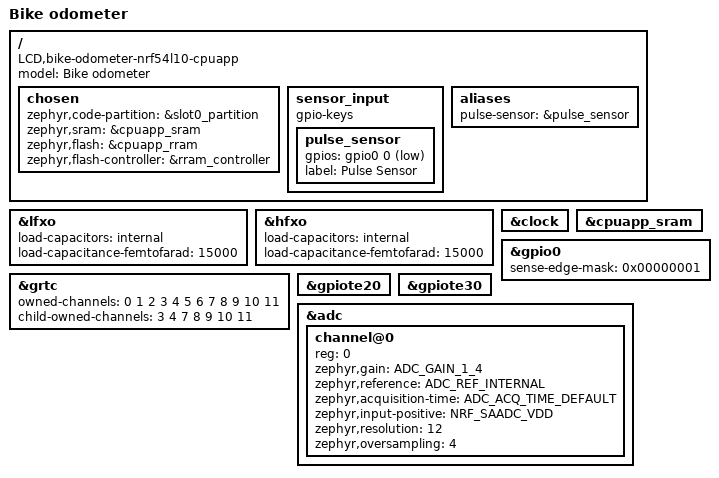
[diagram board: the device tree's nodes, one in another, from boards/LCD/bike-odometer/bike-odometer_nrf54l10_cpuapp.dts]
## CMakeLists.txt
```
#
# Copyright (c) 2018 Nordic Semiconductor
#
# SPDX-License-Identifier: LicenseRef-Nordic-5-Clause
#
cmake_minimum_required(VERSION 3.20.0)

find_package(Zephyr REQUIRED HINTS $ENV{ZEPHYR_BASE})
project(bike-odometer)

# NORDIC SDK APP START
target_sources(app PRIVATE
  src/main.c
  src/odometer.c
  src/ble_service.c
  src/battery.c
  src/rtc.c
)

# NORDIC SDK APP END
```

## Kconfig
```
#
# Copyright (c) 2018 Nordic Semiconductor
#
# SPDX-License-Identifier: LicenseRef-Nordic-5-Clause
#

source "Kconfig.zephyr"

menu "Bike Odometer"

endmenu
```

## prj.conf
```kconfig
CONFIG_BT=y
CONFIG_BT_PERIPHERAL=y
CONFIG_BT_DEVICE_NAME="Bike_Odometer"
CONFIG_BT_DEVICE_APPEARANCE=1154


# Enable NVS for non-volatile storage of trips
# Settings still needed for RTC module
CONFIG_SETTINGS=y
CONFIG_NVS=y
CONFIG_SETTINGS_NVS=y
CONFIG_FLASH=y
CONFIG_FLASH_MAP=y
CONFIG_FLASH_PAGE_LAYOUT=y
CONFIG_MPU_ALLOW_FLASH_WRITE=y

# ADC for battery voltage measurement
CONFIG_ADC=y
```

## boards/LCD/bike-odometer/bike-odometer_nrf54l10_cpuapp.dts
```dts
/dts-v1/;
#include <nordic/nrf54l10_cpuapp.dtsi>
#include <zephyr/dt-bindings/adc/nrf-saadc.h>
#include <zephyr/dt-bindings/adc/adc.h>
#include <zephyr/dt-bindings/gpio/gpio.h>
#include "bike-odometer-pinctrl.dtsi"

/ {
	model = "Bike odometer";
	compatible = "LCD,bike-odometer-nrf54l10-cpuapp";

	chosen {
		zephyr,code-partition = &slot0_partition;
		zephyr,sram = &cpuapp_sram;
		zephyr,flash = &cpuapp_rram;
		zephyr,flash-controller = &rram_controller;
	};

	/* Sensor input on P0.00 */
	sensor_input {
		compatible = "gpio-keys";
		pulse_sensor: pulse_sensor {
			gpios = <&gpio0 0 ( GPIO_ACTIVE_LOW)>;
			label = "Pulse Sensor";
		};
	};

	aliases {
		pulse-sensor = &pulse_sensor;
	};
};

/* 32.768 kHz external crystal (LSE) */
&lfxo {
	load-capacitors = "internal";
	load-capacitance-femtofarad = <15000>;  /* Adjust based on your crystal */
};

/* 32 MHz external crystal (HSE) */
&hfxo {
	load-capacitors = "internal";
	load-capacitance-femtofarad = <15000>;  /* Adjust based on your crystal */
};

&clock {
	status = "okay";
};

&grtc {
	owned-channels = <0 1 2 3 4 5 6 7 8 9 10 11>;
	/* Channels 7-11 reserved for Zero Latency IRQs, 3-4 for FLPR */
	child-owned-channels = <3 4 7 8 9 10 11>;
	status = "okay";
};

&cpuapp_sram {
	status = "okay";
};

&gpio0 {
	/* Use the always-on GPIO SENSE path for the Hall input so an edge on
	 * P0.00 reliably wakes the CPU while the application is parked.
	 */
	sense-edge-mask = <0x00000001>;
	status = "okay";
};

&gpiote20 {
	status = "okay";
};

&gpiote30 {
	status = "okay";
};

&adc {
	#address-cells = <1>;
	#size-cells = <0>;
	status = "okay";

	/* VDD measurement channel */
	channel@0 {
		reg = <0>;
		/* 0.9 V internal reference / 1/4 gain gives a 3.6 V VDD range. */
		zephyr,gain = "ADC_GAIN_1_4";
		zephyr,reference = "ADC_REF_INTERNAL";
		zephyr,acquisition-time = <ADC_ACQ_TIME_DEFAULT>;
		zephyr,input-positive = <NRF_SAADC_VDD>;  /* Internal VDD */
		zephyr,resolution = <12>;
		zephyr,oversampling = <4>;
	};
};

#include <vendor/nordic/nrf54l10_cpuapp_partition.dtsi>
```

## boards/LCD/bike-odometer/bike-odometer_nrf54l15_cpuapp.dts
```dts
/dts-v1/;
#include <nordic/nrf54l15_cpuapp.dtsi>
#include <zephyr/dt-bindings/adc/nrf-saadc.h>
#include <zephyr/dt-bindings/adc/adc.h>
#include <zephyr/dt-bindings/gpio/gpio.h>
#include "bike-odometer-pinctrl.dtsi"

/ {
	model = "Bike odometer";
	compatible = "LCD,bike-odometer-cpuapp";

	chosen {
		zephyr,code-partition = &slot0_partition;
		zephyr,sram = &cpuapp_sram;
		zephyr,flash = &cpuapp_rram;
		zephyr,flash-controller = &rram_controller;
	};

	/* Sensor input on P0.00 */
	sensor_input {
		compatible = "gpio-keys";
		pulse_sensor: pulse_sensor {
			gpios = <&gpio0 0 ( GPIO_ACTIVE_LOW)>;
			label = "Pulse Sensor";
		};
	};

	aliases {
		pulse-sensor = &pulse_sensor;
	};
};

/* 32.768 kHz external crystal (LSE) */
&lfxo {
	load-capacitors = "internal";
	load-capacitance-femtofarad = <15000>;  /* Adjust based on your crystal */
};

/* 32 MHz external crystal (HSE) */
&hfxo {
	load-capacitors = "internal";
	load-capacitance-femtofarad = <15000>;  /* Adjust based on your crystal */
};

&clock {
	status = "okay";
};

&grtc {
	owned-channels = <0 1 2 3 4 5 6 7 8 9 10 11>;
	/* Channels 7-11 reserved for Zero Latency IRQs, 3-4 for FLPR */
	child-owned-channels = <3 4 7 8 9 10 11>;
	status = "okay";
};

&cpuapp_sram {
	status = "okay";
};

&gpio0 {
	status = "okay";
};

&gpiote20 {
	status = "okay";
};

&gpiote30 {
	status = "okay";
};

&adc {
	#address-cells = <1>;
	#size-cells = <0>;
	status = "okay";

	/* VDD measurement channel */
	channel@0 {
		reg = <0>;
		zephyr,gain = "ADC_GAIN_1_6";
		zephyr,reference = "ADC_REF_INTERNAL";
		zephyr,acquisition-time = <ADC_ACQ_TIME_DEFAULT>;
		zephyr,input-positive = <NRF_SAADC_VDD>;  /* Internal VDD */
		zephyr,resolution = <12>;
		zephyr,oversampling = <4>;
	};
};

#include <nordic/nrf54l15_partition.dtsi>
```

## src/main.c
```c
/*
 * Bike Odometer - Main application
 *
 * Tracks bike travel distance using a magnet sensor on the wheel.
 * Aggregates pulses into 5-minute bins and exposes data via BLE.
 */

#include <zephyr/kernel.h>
#include <zephyr/settings/settings.h>
#include <hal/nrf_regulators.h>


#include "battery.h"
#include "odometer.h"
#include "ble_service.h"
#include "rtc.h"

#define BOOT_ADVERTISING_SECONDS 60U

static void enable_dcdc(void)
{
	/* INDUCTORDET is only valid while VREGMAIN DC/DC is disabled. */
	bool inductor_detected = nrf_regulators_inductor_check(NRF_REGULATORS);


	if (!inductor_detected) {
		return;
	}

	nrf_regulators_vreg_enable_set(NRF_REGULATORS,
					NRF_REGULATORS_VREG_MAIN, true);
}

int main(void)
{
	int err;

	enable_dcdc();

	/* Measure battery FIRST before any other subsystems
	 * to minimize load on CR2032 (high internal resistance)
	 */
	err = battery_measure();
	if (err) {
		/* Continue - battery info will just be unavailable */
	}

	/* Initialize BLE */
	err = ble_service_init();
	if (err) {
		return 0;
	}

	/* Load saved data from NVM */
	odometer_load_from_nvm();

	/* Initialize settings subsystem (for RTC) and load */
	err = settings_subsys_init();
	if (err) {
	} else {
		settings_load();
	}

	/* Initialize RTC (after settings loaded) */
	rtc_init();

	/* Initialize odometer (pulse GPIO and bin timer) */
	err = odometer_init();
	if (err) {
		/* Continue - BLE will still work */
	}

	/* Allow setup/sync after boot, then leave the radio idle. */
	ble_service_start_advertising_for(BOOT_ADVERTISING_SECONDS);

	/* Main loop */
	for (;;) {
		k_sleep(K_FOREVER);
	}
}
```

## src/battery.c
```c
/*
 * Battery module - CR2032 voltage estimation via ADC
 *
 * Uses SAADC internal VDD channel to measure supply voltage.
 * CR2032 discharge curve (approximation):
 *   3.0V = 100% (fresh)
 *   2.9V = 80%
 *   2.8V = 40%
 *   2.75V = 20%
 *   2.7V = 0% (observed reliable product cutoff)
 */

#include "battery.h"

#include <zephyr/kernel.h>
#include <zephyr/drivers/adc.h>
#include <zephyr/devicetree.h>


/* ADC configuration from devicetree */
#define ADC_NODE DT_NODELABEL(adc)
#define ADC_CHANNEL_NODE DT_CHILD(ADC_NODE, channel_0)
#define ADC_CHANNEL_ID 0
#define ADC_RESOLUTION 12

/*
 * The nRF54L internal reference is 0.9 V. With 1/4 channel gain the VDD
 * input range is 3.6 V, so VDD (mV) = raw * 3600 / 4095.
 */
#define ADC_FULL_SCALE_MV 3600

static const struct device *adc_dev;
static uint16_t battery_voltage_mv;
static uint8_t battery_percent;
static bool adc_initialized;

static int16_t adc_buffer;

/* Channel config from devicetree */
static const struct adc_channel_cfg channel_cfg = ADC_CHANNEL_CFG_DT(ADC_CHANNEL_NODE);

static struct adc_sequence sequence = {
	.channels = BIT(ADC_CHANNEL_ID),
	.buffer = &adc_buffer,
	.buffer_size = sizeof(adc_buffer),
	.resolution = ADC_RESOLUTION,
};

/*
 * Convert ADC raw value to millivolts
 * VDD (mV) = raw * ADC_FULL_SCALE_MV / 4095
 */
static uint16_t adc_raw_to_mv(int16_t raw)
{
	if (raw < 0) {
		return 0;
	}
	return (uint16_t)((raw * (uint32_t)ADC_FULL_SCALE_MV) / 4095UL);
}

/*
 * Map CR2032 voltage to battery percentage
 * This is usable product capacity, not the CR2032's remaining chemical
 * capacity. Although the nRF54L can operate down to 1.7 V, an aged CR2032
 * develops enough internal resistance that BLE/RRAM current pulses can cause
 * brownouts while its resting voltage is still much higher. Hardware testing
 * found 2.70 V to be the reliable cutoff for this board.
 */
static uint8_t voltage_to_percent(uint16_t mv)
{
	/* CR2032 voltage thresholds (mV) and corresponding percentages */
	static const struct {
		uint16_t mv;
		uint8_t percent;
	} curve[] = {
		{ 3000, 100 },
		{ 2900,  80 },
		{ 2800,  40 },
		{ 2750,  20 },
		{ 2700,   0 },
	};

	/* Above max */
	if (mv >= curve[0].mv) {
		return curve[0].percent;
	}

	/* Below min */
	if (mv <= curve[ARRAY_SIZE(curve) - 1].mv) {
		return curve[ARRAY_SIZE(curve) - 1].percent;
	}

	/* Linear interpolation between curve points */
	for (size_t i = 0; i < ARRAY_SIZE(curve) - 1; i++) {
		if (mv >= curve[i + 1].mv) {
			uint16_t v_high = curve[i].mv;
			uint16_t v_low = curve[i + 1].mv;
			uint8_t p_high = curve[i].percent;
			uint8_t p_low = curve[i + 1].percent;

			/* Interpolate */
			uint16_t v_range = v_high - v_low;
			uint8_t p_range = p_high - p_low;
			uint16_t v_offset = mv - v_low;

			return p_low + (uint8_t)((v_offset * p_range) / v_range);
		}
	}

	return 0;
}

int battery_measure(void)
{
	int err;

	if (!adc_initialized) {
		adc_dev = DEVICE_DT_GET(ADC_NODE);
		if (!device_is_ready(adc_dev)) {
			return -ENODEV;
		}

		err = adc_channel_setup(adc_dev, &channel_cfg);
		if (err) {
			return err;
		}
		adc_initialized = true;
	}

	/* Small delay to let voltage stabilize after boot */
	k_sleep(K_MSEC(10));

	/* Take multiple readings and average for better accuracy */
	int32_t sum = 0;
	const int num_readings = 4;

	for (int i = 0; i < num_readings; i++) {
		adc_buffer = 0;
		err = adc_read(adc_dev, &sequence);
		if (err) {
			return err;
		}
		sum += adc_buffer;
		k_sleep(K_MSEC(5));  /* Brief delay between readings */
	}

	int16_t avg_raw = (int16_t)(sum / num_readings);
	battery_voltage_mv = adc_raw_to_mv(avg_raw);
	battery_percent = voltage_to_percent(battery_voltage_mv);


	return 0;
}

uint16_t battery_get_voltage_mv(void)
{
	return battery_voltage_mv;
}

uint8_t battery_get_percent(void)
{
	return battery_percent;
}
```

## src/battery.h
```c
/*
 * Battery module - CR2032 voltage estimation via ADC
 */

#ifndef BATTERY_H
#define BATTERY_H

#include <stdint.h>

/**
 * @brief Read battery voltage and estimate charge level
 * 
 * Should be called early at boot with minimal system load
 * to get accurate reading given CR2032 high internal resistance.
 * 
 * @return 0 on success, negative errno on failure
 */
int battery_measure(void);

/**
 * @brief Get last measured battery voltage in millivolts
 */
uint16_t battery_get_voltage_mv(void);

/**
 * @brief Get estimated battery percentage (0-100)
 */
uint8_t battery_get_percent(void);

#endif /* BATTERY_H */
```

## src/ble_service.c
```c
/*
 * BLE Service module - GATT service and advertising
 */

#include "ble_service.h"
#include "odometer.h"
#include "battery.h"
#include "rtc.h"

#include <zephyr/kernel.h>
#include <zephyr/sys/atomic.h>
#include <zephyr/bluetooth/bluetooth.h>
#include <zephyr/bluetooth/hci.h>
#include <zephyr/bluetooth/conn.h>
#include <zephyr/bluetooth/uuid.h>
#include <zephyr/bluetooth/gatt.h>
#include <zephyr/bluetooth/att.h>
#include <zephyr/sys/util.h>
#include <stdio.h>
#include <stdlib.h>
#include <stdbool.h>
#include <string.h>


#define DEVICE_NAME             CONFIG_BT_DEVICE_NAME
#define DEVICE_NAME_SUFFIX_LEN  5
#define DEVICE_NAME_MAX_LEN     (sizeof(DEVICE_NAME) - 1 + DEVICE_NAME_SUFFIX_LEN)
#define TRIPS_NOTIFY_STACK_SIZE 2048

/* Advertising work */
static struct k_work adv_work;
static struct k_work adv_stop_work;
static struct k_work_delayable adv_timeout_work;
static struct bt_conn *current_conn;
static atomic_t advertising;
static atomic_t connected_state;
static atomic_t requested_adv_seconds;
static struct k_work_q trips_notify_work_q;
static struct k_work trips_notify_work;
K_THREAD_STACK_DEFINE(trips_notify_stack, TRIPS_NOTIFY_STACK_SIZE);
static char device_name[DEVICE_NAME_MAX_LEN + 1];
static const struct bt_gatt_attr *trips_value_attr;

static void update_device_name(void)
{
	bt_addr_le_t addr;
	size_t count = 1;
	size_t base_len = sizeof(DEVICE_NAME) - 1;
	int written;

	memcpy(device_name, DEVICE_NAME, base_len);
	device_name[base_len] = '\0';

	bt_id_get(&addr, &count);
	if (count == 0U) {
		return;
	}

	written = snprintf(device_name, sizeof(device_name), "%s-%02X%02X",
				 DEVICE_NAME,
				 addr.a.val[1],
				 addr.a.val[0]);
	if (written < 0 || written >= (int)sizeof(device_name)) {
		memcpy(device_name, DEVICE_NAME, base_len);
		device_name[base_len] = '\0';
		return;
	}

}

/*
 * BLE read handler for pulse count
 */
/*
 * BLE read handler for battery info
 */
static ssize_t read_battery(struct bt_conn *conn,
							const struct bt_gatt_attr *attr,
							void *buf, uint16_t len, uint16_t offset)
{
	uint16_t voltage_mv = battery_get_voltage_mv();
	uint8_t percent = battery_get_percent();

	char str[32];
	int n = snprintf(str, sizeof(str), "{\"mv\":%u,\"pct\":%u}", voltage_mv, percent);
	if (n < 0) {
		return BT_GATT_ERR(BT_ATT_ERR_UNLIKELY);
	}

	return bt_gatt_attr_read(conn, attr, buf, len, offset, str, (size_t)n);
}

/*
 * BLE read handler for pulse count
 */
static ssize_t read_pulse(struct bt_conn *conn,
						  const struct bt_gatt_attr *attr,
						  void *buf, uint16_t len, uint16_t offset)
{
	uint32_t pulses = odometer_get_pulse_count();

	char str[16];
	int n = snprintf(str, sizeof(str), "%u", pulses);
	if (n < 0) {
		return BT_GATT_ERR(BT_ATT_ERR_UNLIKELY);
	}

	return bt_gatt_attr_read(conn, attr, buf, len, offset, str, (size_t)n);
}

/*
 * BLE read handler for trips JSON
 */
static ssize_t read_trips(struct bt_conn *conn,
						  const struct bt_gatt_attr *attr,
						  void *buf, uint16_t len, uint16_t offset)
{
	size_t trip_count = odometer_get_trip_count();
	struct trip_entry trip;

	static char out[BT_ATT_MAX_ATTRIBUTE_LEN];
	size_t pos = 0;
	int written = snprintf(out, sizeof(out), "{\"trips\":[");
	if (written < 0 || (size_t)written >= sizeof(out)) {
		return BT_GATT_ERR(BT_ATT_ERR_UNLIKELY);
	}
	pos = (size_t)written;

	for (size_t t = 0; t < trip_count; t++) {
		char trip_json[1024];
		size_t tpos = 0;
		uint32_t trip_id;

		if (odometer_read_trip(t, &trip) != 0) {
			continue;
		}

		trip_id = odometer_get_trip_id(t);

		written = snprintf(trip_json + tpos, sizeof(trip_json) - tpos,
					   "%s{\"id\":%u,\"startDate\":%llu,\"buckets\":[",
					   (t > 0) ? "," : "",
					   trip_id,
					   (unsigned long long)trip.start_timestamp_s);
		if (written < 0 || (size_t)written >= (sizeof(trip_json) - tpos)) {
			break;
		}
		tpos += (size_t)written;

		for (uint16_t i = 0; i < trip.bucket_count; i++) {
			written = snprintf(trip_json + tpos, sizeof(trip_json) - tpos,
					   "%s%u", (i > 0) ? "," : "", trip.buckets[i]);
			if (written < 0 || (size_t)written >= (sizeof(trip_json) - tpos)) {
				goto done_trips;
			}
			tpos += (size_t)written;
		}

		written = snprintf(trip_json + tpos, sizeof(trip_json) - tpos, "]}");
		if (written < 0 || (size_t)written >= (sizeof(trip_json) - tpos)) {
			break;
		}
		tpos += (size_t)written;

		if (tpos >= (sizeof(out) - pos - 2)) {
			break;
		}

		memcpy(out + pos, trip_json, tpos);
		pos += tpos;
	}

done_trips:
	written = snprintf(out + pos, sizeof(out) - pos, "]}");
	if (written < 0 || (size_t)written >= (sizeof(out) - pos)) {
		return BT_GATT_ERR(BT_ATT_ERR_UNLIKELY);
	}
	pos += (size_t)written;

	return bt_gatt_attr_read(conn, attr, buf, len, offset, out, pos);
}

/* Service and characteristic UUIDs */
static struct bt_uuid_128 bike_svc_uuid = BT_UUID_INIT_128(
	0x78,0x56,0x34,0x12,0x34,0x12,0x78,0x56,0x12,0x34,0x56,0x78,0x12,0x34,0x56,0x78);

static struct bt_uuid_128 bike_pulse_uuid = BT_UUID_INIT_128(
	0x79,0x56,0x34,0x12,0x34,0x12,0x78,0x56,0x12,0x34,0x56,0x78,0x12,0x34,0x56,0x78);

static struct bt_uuid_128 bike_trips_uuid = BT_UUID_INIT_128(
	0x88,0x56,0x34,0x12,0x34,0x12,0x78,0x56,0x12,0x34,0x56,0x78,0x12,0x34,0x56,0x78);

static struct bt_uuid_128 bike_battery_uuid = BT_UUID_INIT_128(
	0x8A,0x56,0x34,0x12,0x34,0x12,0x78,0x56,0x12,0x34,0x56,0x78,0x12,0x34,0x56,0x78);

static struct bt_uuid_128 bike_time_uuid = BT_UUID_INIT_128(
	0x8B,0x56,0x34,0x12,0x34,0x12,0x78,0x56,0x12,0x34,0x56,0x78,0x12,0x34,0x56,0x78);

static struct bt_uuid_128 bike_wheelsize_uuid = BT_UUID_INIT_128(
	0x8D,0x56,0x34,0x12,0x34,0x12,0x78,0x56,0x12,0x34,0x56,0x78,0x12,0x34,0x56,0x78);

enum trips_stream_phase {
	TRIPS_STREAM_START,
	TRIPS_STREAM_TRIP_START,
	TRIPS_STREAM_BUCKET,
	TRIPS_STREAM_TRIP_END,
	TRIPS_STREAM_END,
	TRIPS_STREAM_DONE,
};

struct trips_stream_state {
	bool notify_enabled;
	bool active;
	bool notify_in_progress;
	bool sent_any_trip;
	enum trips_stream_phase phase;
	size_t phase_offset;
	size_t trip_count;
	size_t trip_index;
	uint32_t trip_id;
	uint16_t bucket_index;
	struct trip_entry trip;
	struct bt_gatt_notify_params notify_params;
	char notify_buf[CONFIG_BT_L2CAP_TX_MTU];
};

static struct trips_stream_state trips_stream;

static void trips_notify_work_handler(struct k_work *work);
static void trips_notify_complete(struct bt_conn *conn, void *user_data);
static void trips_ccc_changed(const struct bt_gatt_attr *attr, uint16_t value);
static ssize_t write_trips(struct bt_conn *conn,
					   const struct bt_gatt_attr *attr,
					   const void *buf, uint16_t len,
					   uint16_t offset, uint8_t flags);

static void trips_stream_reset(void)
{
	trips_stream.active = false;
	trips_stream.sent_any_trip = false;
	trips_stream.notify_in_progress = false;
	trips_stream.phase = TRIPS_STREAM_DONE;
	trips_stream.phase_offset = 0;
	trips_stream.trip_count = 0;
	trips_stream.trip_index = 0;
	trips_stream.trip_id = 0;
	trips_stream.bucket_index = 0;
}

static size_t trips_stream_append(char *dst, size_t dst_len, size_t dst_pos,
					  const char *src, size_t src_len,
					  size_t *src_offset)
{
	size_t remaining = src_len - *src_offset;
	size_t space = dst_len - dst_pos;
	size_t copy_len = MIN(remaining, space);

	if (copy_len == 0U) {
		return 0U;
	}

	memcpy(dst + dst_pos, src + *src_offset, copy_len);
	*src_offset += copy_len;

	return copy_len;
}

static void trips_stream_advance_to_next_trip(void)
{
	while (trips_stream.trip_index < trips_stream.trip_count) {
		if (odometer_read_trip(trips_stream.trip_index, &trips_stream.trip) == 0) {
			trips_stream.trip_id = odometer_get_trip_id(trips_stream.trip_index);
			trips_stream.phase = TRIPS_STREAM_TRIP_START;
			trips_stream.phase_offset = 0;
			trips_stream.bucket_index = 0;
			trips_stream.trip_index++;
			return;
		}

		trips_stream.trip_index++;
	}

	trips_stream.phase = TRIPS_STREAM_END;
	trips_stream.phase_offset = 0;
}

static size_t trips_stream_build_chunk(char *chunk, size_t chunk_size)
{
	static const char stream_start[] = "{\"trips\":[";
	static const char stream_end[] = "]}";
	static const char trip_end[] = "]}";
	size_t len = 0;

	while (len < chunk_size && trips_stream.phase != TRIPS_STREAM_DONE) {
		char part[112];
		size_t part_len = 0;
		size_t copied;
		int written;

		switch (trips_stream.phase) {
		case TRIPS_STREAM_START:
			copied = trips_stream_append(chunk, chunk_size, len,
						    stream_start, sizeof(stream_start) - 1,
						    &trips_stream.phase_offset);
			len += copied;
			if (trips_stream.phase_offset == sizeof(stream_start) - 1) {
				trips_stream.phase_offset = 0;
				trips_stream_advance_to_next_trip();
			}
			break;

		case TRIPS_STREAM_TRIP_START:
			written = snprintf(part, sizeof(part), "%s{\"id\":%u,\"startDate\":%llu,\"buckets\":[",
					   trips_stream.sent_any_trip ? "," : "",
					   trips_stream.trip_id,
					   (unsigned long long)trips_stream.trip.start_timestamp_s);
			if (written < 0 || (size_t)written >= sizeof(part)) {
				trips_stream_reset();
				return 0;
			}

			part_len = (size_t)written;
			copied = trips_stream_append(chunk, chunk_size, len,
						    part, part_len,
						    &trips_stream.phase_offset);
			len += copied;
			if (trips_stream.phase_offset == part_len) {
				trips_stream.phase_offset = 0;
				trips_stream.sent_any_trip = true;
				trips_stream.phase = trips_stream.trip.bucket_count > 0 ?
					TRIPS_STREAM_BUCKET : TRIPS_STREAM_TRIP_END;
			}
			break;

		case TRIPS_STREAM_BUCKET:
			written = snprintf(part, sizeof(part), "%s%u",
					   trips_stream.bucket_index > 0 ? "," : "",
					   trips_stream.trip.buckets[trips_stream.bucket_index]);
			if (written < 0 || (size_t)written >= sizeof(part)) {
				trips_stream_reset();
				return 0;
			}

			part_len = (size_t)written;
			copied = trips_stream_append(chunk, chunk_size, len,
						    part, part_len,
						    &trips_stream.phase_offset);
			len += copied;
			if (trips_stream.phase_offset == part_len) {
				trips_stream.phase_offset = 0;
				trips_stream.bucket_index++;
				if (trips_stream.bucket_index >= trips_stream.trip.bucket_count) {
					trips_stream.phase = TRIPS_STREAM_TRIP_END;
				}
			}
			break;

		case TRIPS_STREAM_TRIP_END:
			copied = trips_stream_append(chunk, chunk_size, len,
						    trip_end, sizeof(trip_end) - 1,
						    &trips_stream.phase_offset);
			len += copied;
			if (trips_stream.phase_offset == sizeof(trip_end) - 1) {
				trips_stream.phase_offset = 0;
				trips_stream_advance_to_next_trip();
			}
			break;

		case TRIPS_STREAM_END:
			copied = trips_stream_append(chunk, chunk_size, len,
						    stream_end, sizeof(stream_end) - 1,
						    &trips_stream.phase_offset);
			len += copied;
			if (trips_stream.phase_offset == sizeof(stream_end) - 1) {
				trips_stream.phase_offset = 0;
				trips_stream.phase = TRIPS_STREAM_DONE;
				trips_stream.active = false;
			}
			break;

		case TRIPS_STREAM_DONE:
		default:
			break;
		}

		if (copied == 0U) {
			break;
		}
	}

	return len;
}

static void trips_stream_start(void)
{
	trips_stream.active = true;
	trips_stream.sent_any_trip = false;
	trips_stream.phase = TRIPS_STREAM_START;
	trips_stream.phase_offset = 0;
	trips_stream.trip_count = odometer_get_trip_count();
	trips_stream.trip_index = 0;
	trips_stream.trip_id = 0;
	trips_stream.bucket_index = 0;

	k_work_submit_to_queue(&trips_notify_work_q, &trips_notify_work);
}

static void trips_notify_complete(struct bt_conn *conn, void *user_data)
{
	ARG_UNUSED(conn);
	ARG_UNUSED(user_data);

	trips_stream.notify_in_progress = false;
	if (trips_stream.active) {
		k_work_submit_to_queue(&trips_notify_work_q, &trips_notify_work);
	} else {
	}
}

static void trips_notify_work_handler(struct k_work *work)
{
	struct bt_conn *conn = current_conn;
	size_t mtu_payload;
	size_t chunk_len;
	int err;

	ARG_UNUSED(work);

	if (!trips_stream.active || trips_stream.notify_in_progress || !trips_stream.notify_enabled || conn == NULL) {
		return;
	}

	mtu_payload = bt_gatt_get_mtu(conn);
	if (mtu_payload > 3U) {
		mtu_payload -= 3U;
	}
	mtu_payload = MIN(mtu_payload, sizeof(trips_stream.notify_buf));

	chunk_len = trips_stream_build_chunk(trips_stream.notify_buf, mtu_payload);
	if (chunk_len == 0U) {
		return;
	}

	trips_stream.notify_params.uuid = &bike_trips_uuid.uuid;
	if (trips_value_attr == NULL) {
		trips_stream_reset();
		return;
	}
	trips_stream.notify_params.attr = trips_value_attr;
	trips_stream.notify_params.data = trips_stream.notify_buf;
	trips_stream.notify_params.len = (uint16_t)chunk_len;
	trips_stream.notify_params.func = trips_notify_complete;
	trips_stream.notify_params.user_data = NULL;
	trips_stream.notify_in_progress = true;

	err = bt_gatt_notify_cb(conn, &trips_stream.notify_params);
	if (err) {
		trips_stream.notify_in_progress = false;
		trips_stream_reset();
	}
}

static void trips_ccc_changed(const struct bt_gatt_attr *attr, uint16_t value)
{
	ARG_UNUSED(attr);

	trips_stream.notify_enabled = (value & BT_GATT_CCC_NOTIFY) != 0U;
	if (!trips_stream.notify_enabled) {
		trips_stream_reset();
	}
}

static ssize_t write_trips(struct bt_conn *conn,
					   const struct bt_gatt_attr *attr,
					   const void *buf, uint16_t len,
					   uint16_t offset, uint8_t flags)
{
	char command[16];

	ARG_UNUSED(attr);
	ARG_UNUSED(flags);

	if (trips_value_attr == NULL) {
		trips_value_attr = attr;
	}

	if (offset != 0U) {
		return BT_GATT_ERR(BT_ATT_ERR_INVALID_OFFSET);
	}

	if (len >= sizeof(command)) {
		return BT_GATT_ERR(BT_ATT_ERR_INVALID_ATTRIBUTE_LEN);
	}

	memcpy(command, buf, len);
	command[len] = '\0';

	if (len == 0U || strcmp(command, "start") == 0 || strcmp(command, "1") == 0) {
		if (!trips_stream.notify_enabled) {
			return BT_GATT_ERR(BT_ATT_ERR_CCC_IMPROPER_CONF);
		}

		if (conn == NULL || conn != current_conn) {
			return BT_GATT_ERR(BT_ATT_ERR_UNLIKELY);
		}

		if (trips_stream.active || trips_stream.notify_in_progress) {
			return BT_GATT_ERR(BT_ATT_ERR_PROCEDURE_IN_PROGRESS);
		}

		trips_stream_start();
		return len;
	}

	if (strcmp(command, "cancel") == 0) {
		trips_stream_reset();
		return len;
	}

	return BT_GATT_ERR(BT_ATT_ERR_VALUE_NOT_ALLOWED);
}

/*
 * BLE read handler for wheel size (returns "26.30" format)
 */
static ssize_t read_wheelsize(struct bt_conn *conn,
							  const struct bt_gatt_attr *attr,
							  void *buf, uint16_t len, uint16_t offset)
{
	uint32_t size_x100 = odometer_get_wheel_size_x100();
	char str[16];
	int n = snprintf(str, sizeof(str), "%u.%02u", size_x100 / 100, size_x100 % 100);
	if (n < 0) {
		return BT_GATT_ERR(BT_ATT_ERR_UNLIKELY);
	}
	return bt_gatt_attr_read(conn, attr, buf, len, offset, str, (size_t)n);
}

/*
 * BLE write handler for wheel size (expects "26.30" format)
 */
static ssize_t write_wheelsize(struct bt_conn *conn,
							   const struct bt_gatt_attr *attr,
							   const void *buf, uint16_t len,
							   uint16_t offset, uint8_t flags)
{
	if (offset != 0) {
		return BT_GATT_ERR(BT_ATT_ERR_INVALID_OFFSET);
	}

	char str[16];
	if (len >= sizeof(str)) {
		return BT_GATT_ERR(BT_ATT_ERR_INVALID_ATTRIBUTE_LEN);
	}

	memcpy(str, buf, len);
	str[len] = '\0';

	/* Parse "26.30" format */
	char *dot = strchr(str, '.');
	uint32_t whole = (uint32_t)strtoul(str, NULL, 10);
	uint32_t frac = 0;
	if (dot && dot[1]) {
		frac = (uint32_t)strtoul(dot + 1, NULL, 10);
		/* Handle single digit fraction (e.g., "26.3" -> 30) */
		if (dot[2] == '\0') {
			frac *= 10;
		}
	}

	uint32_t size_x100 = whole * 100 + frac;
	if (size_x100 < 1000 || size_x100 > 4000) {
		/* Sanity check: 10" - 40" range */
		return BT_GATT_ERR(BT_ATT_ERR_VALUE_NOT_ALLOWED);
	}

	odometer_set_wheel_size_x100(size_x100);

	return len;
}

/*
 * BLE read handler for time
 */
static ssize_t read_time(struct bt_conn *conn,
						 const struct bt_gatt_attr *attr,
						 void *buf, uint16_t len, uint16_t offset)
{
	uint64_t unix_time = rtc_get_time();

	char str[32];
	int n = snprintf(str, sizeof(str), "%llu", (unsigned long long)unix_time);
	if (n < 0) {
		return BT_GATT_ERR(BT_ATT_ERR_UNLIKELY);
	}

	return bt_gatt_attr_read(conn, attr, buf, len, offset, str, (size_t)n);
}

/*
 * BLE write handler for time
 */
static ssize_t write_time(struct bt_conn *conn,
						  const struct bt_gatt_attr *attr,
						  const void *buf, uint16_t len,
						  uint16_t offset, uint8_t flags)
{
	if (offset != 0) {
		return BT_GATT_ERR(BT_ATT_ERR_INVALID_OFFSET);
	}

	/* Parse unix timestamp from string */
	char str[32];
	if (len >= sizeof(str)) {
		return BT_GATT_ERR(BT_ATT_ERR_INVALID_ATTRIBUTE_LEN);
	}

	memcpy(str, buf, len);
	str[len] = '\0';

	uint64_t unix_time = strtoull(str, NULL, 10);
	if (unix_time == 0) {
		return BT_GATT_ERR(BT_ATT_ERR_VALUE_NOT_ALLOWED);
	}

	rtc_set_time(unix_time);

	return len;
}

/* GATT service definition */
BT_GATT_SERVICE_DEFINE(bike_svc,
	BT_GATT_PRIMARY_SERVICE(&bike_svc_uuid.uuid),
	BT_GATT_CHARACTERISTIC(&bike_pulse_uuid.uuid,
						   BT_GATT_CHRC_READ,
						   BT_GATT_PERM_READ,
						   read_pulse, NULL, NULL),
	BT_GATT_CUD("Pulse", BT_GATT_PERM_READ),
	BT_GATT_CHARACTERISTIC(&bike_trips_uuid.uuid,
					   BT_GATT_CHRC_READ | BT_GATT_CHRC_WRITE | BT_GATT_CHRC_NOTIFY,
					   BT_GATT_PERM_READ | BT_GATT_PERM_WRITE,
					   read_trips, write_trips, NULL),
	BT_GATT_CUD("Trips", BT_GATT_PERM_READ),
	BT_GATT_CCC(trips_ccc_changed, BT_GATT_PERM_READ | BT_GATT_PERM_WRITE),
	BT_GATT_CHARACTERISTIC(&bike_battery_uuid.uuid,
						   BT_GATT_CHRC_READ,
						   BT_GATT_PERM_READ,
						   read_battery, NULL, NULL),
	BT_GATT_CUD("Battery", BT_GATT_PERM_READ),
	BT_GATT_CHARACTERISTIC(&bike_time_uuid.uuid,
						   BT_GATT_CHRC_READ | BT_GATT_CHRC_WRITE,
						   BT_GATT_PERM_READ | BT_GATT_PERM_WRITE,
						   read_time, write_time, NULL),
	BT_GATT_CUD("Time", BT_GATT_PERM_READ),
	BT_GATT_CHARACTERISTIC(&bike_wheelsize_uuid.uuid,
						   BT_GATT_CHRC_READ | BT_GATT_CHRC_WRITE,
						   BT_GATT_PERM_READ | BT_GATT_PERM_WRITE,
						   read_wheelsize, write_wheelsize, NULL),
	BT_GATT_CUD("Wheel Size", BT_GATT_PERM_READ),
);

/* Advertising data */
static struct bt_data ad[] = {
	BT_DATA_BYTES(BT_DATA_FLAGS, (BT_LE_AD_GENERAL | BT_LE_AD_NO_BREDR)),
	BT_DATA(BT_DATA_NAME_COMPLETE, device_name, 0),
};

static const struct bt_data sd[] = {
	BT_DATA_BYTES(BT_DATA_UUID128_ALL,
		0x78,0x56,0x34,0x12,0x34,0x12,0x78,0x56,
		0x12,0x34,0x56,0x78,0x12,0x34,0x56,0x78),
};

static void adv_work_handler(struct k_work *work)
{
	uint32_t duration_seconds = (uint32_t)atomic_get(&requested_adv_seconds);
	int err;

	/* A queued start can outlive the request that submitted it. */
	if (duration_seconds == 0U || atomic_get(&connected_state)) {
		return;
	}

	if (atomic_get(&advertising)) {
		k_work_reschedule(&adv_timeout_work, K_SECONDS(duration_seconds));
		return;
	}

	err = bt_le_adv_start(BT_LE_ADV_CONN_FAST_2, ad, ARRAY_SIZE(ad), sd, ARRAY_SIZE(sd));

	if (err) {
		err = bt_le_adv_start(BT_LE_ADV_CONN_FAST_2, ad, ARRAY_SIZE(ad), NULL, 0);
	}

	if (err) {
		return;
	}

	atomic_set(&advertising, 1);
	k_work_reschedule(&adv_timeout_work, K_SECONDS(duration_seconds));
}

static void adv_stop_work_handler(struct k_work *work)
{
	int err;

	/* A movement edge may have opened a new advertising window after this
	 * stop was queued. Never let that stale stop close the new window.
	 */
	if (atomic_get(&requested_adv_seconds) != 0) {
		return;
	}

	if (!atomic_cas(&advertising, 1, 0)) {
		return;
	}

	err = bt_le_adv_stop();
	if (err) {
		atomic_set(&advertising, 1);
		return;
	}

}

static void adv_timeout_work_handler(struct k_work *work)
{
	atomic_set(&requested_adv_seconds, 0);
	k_work_submit(&adv_stop_work);
}

static void connected(struct bt_conn *conn, uint8_t err)
{
	if (err) {
		return;
	}

	if (current_conn != NULL) {
		bt_conn_unref(current_conn);
	}
	current_conn = bt_conn_ref(conn);
	atomic_set(&connected_state, 1);
	atomic_set(&advertising, 0);
	atomic_set(&requested_adv_seconds, 0);
	k_work_cancel_delayable(&adv_timeout_work);

}

static void disconnected(struct bt_conn *conn, uint8_t reason)
{
	trips_stream_reset();
	trips_stream.notify_enabled = false;

	if (current_conn == conn) {
		bt_conn_unref(current_conn);
		current_conn = NULL;
	}
	atomic_set(&connected_state, 0);

}

static void recycled_cb(void)
{
}

BT_CONN_CB_DEFINE(conn_callbacks) = {
	.connected        = connected,
	.disconnected     = disconnected,
	.recycled         = recycled_cb,
};

/*
 * Public API
 */

int ble_service_init(void)
{
	int err = bt_enable(NULL);
	if (err) {
		return err;
	}

	update_device_name();
	ad[1].data_len = strlen(device_name);

	k_work_init(&adv_work, adv_work_handler);
	k_work_init(&adv_stop_work, adv_stop_work_handler);
	k_work_init_delayable(&adv_timeout_work, adv_timeout_work_handler);
	k_work_init(&trips_notify_work, trips_notify_work_handler);
	k_work_queue_start(&trips_notify_work_q,
			   trips_notify_stack,
			   K_THREAD_STACK_SIZEOF(trips_notify_stack),
			   7,
			   NULL);
	trips_stream_reset();

	return 0;
}

void ble_service_start_advertising_for(uint32_t duration_seconds)
{
	if (duration_seconds == 0U) {
		return;
	}

	atomic_set(&requested_adv_seconds, (atomic_val_t)duration_seconds);
	k_work_submit(&adv_work);
}

void ble_service_stop_advertising(void)
{
	atomic_set(&requested_adv_seconds, 0);
	k_work_cancel_delayable(&adv_timeout_work);
	k_work_submit(&adv_stop_work);
}

bool ble_service_is_connected(void)
{
	return atomic_get(&connected_state) != 0;
}
```

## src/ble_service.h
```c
/*
 * BLE Service module - GATT service and advertising
 */

#ifndef BLE_SERVICE_H
#define BLE_SERVICE_H

#include <stdbool.h>
#include <stdint.h>

/**
 * @brief Initialize BLE (enable Bluetooth stack)
 * @return 0 on success, negative errno on failure
 */
int ble_service_init(void);

/**
 * @brief Start connectable advertising for a limited time
 *
 * If already advertising, the timeout is restarted. If connected, the request
 * is ignored because the radio is already available to the phone.
 *
 * @param duration_seconds Advertising window length in seconds
 */
void ble_service_start_advertising_for(uint32_t duration_seconds);

/**
 * @brief Stop advertising when the device enters parked mode
 */
void ble_service_stop_advertising(void);

/**
 * @brief Return whether a phone is currently connected
 */
bool ble_service_is_connected(void);

#endif /* BLE_SERVICE_H */
```

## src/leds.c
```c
/*
 * LED module - Status LED control
 */

#include "leds.h"

#include <zephyr/kernel.h>
#include <zephyr/drivers/gpio.h>
#include <zephyr/sys/printk.h>

#define LED_GPIO_NODE DT_NODELABEL(gpio0)

#ifndef RUN_STATUS_PIN
#define RUN_STATUS_PIN 13
#endif

#ifndef CON_STATUS_PIN
#define CON_STATUS_PIN 14
#endif

static const struct device *led_dev;
static bool run_led_state;

int leds_init(void)
{
	led_dev = DEVICE_DT_GET(LED_GPIO_NODE);
	if (!device_is_ready(led_dev)) {
		printk("LED GPIO device not ready\n");
		led_dev = NULL;
		return -ENODEV;
	}

	printk("LED GPIO device ready\n");

	/* nRF DK LEDs are active-low; configure with GPIO_ACTIVE_LOW so
	 * logical '1' means LED on and '0' means LED off.
	 */
	int err = gpio_pin_configure(led_dev, RUN_STATUS_PIN, GPIO_OUTPUT_INACTIVE | GPIO_ACTIVE_LOW);
	if (err) {
		printk("Failed to configure RUN LED pin %d (err %d)\n", RUN_STATUS_PIN, err);
		return err;
	}
	printk("Configured RUN LED pin %d\n", RUN_STATUS_PIN);

	err = gpio_pin_configure(led_dev, CON_STATUS_PIN, GPIO_OUTPUT_INACTIVE | GPIO_ACTIVE_LOW);
	if (err) {
		printk("Failed to configure CON LED pin %d (err %d)\n", CON_STATUS_PIN, err);
		return err;
	}
	printk("Configured CON LED pin %d\n", CON_STATUS_PIN);

	return 0;
}

void leds_set_run(bool on)
{
	if (led_dev) {
		gpio_pin_set(led_dev, RUN_STATUS_PIN, on ? 1 : 0);
		run_led_state = on;
	}
}

void leds_set_connection(bool on)
{
	if (led_dev) {
		gpio_pin_set(led_dev, CON_STATUS_PIN, on ? 1 : 0);
	}
}

void leds_toggle_run(void)
{
	run_led_state = !run_led_state;
	leds_set_run(run_led_state);
}
```

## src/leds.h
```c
/*
 * LED module - Status LED control
 */

#ifndef LEDS_H
#define LEDS_H

#include <stdbool.h>

/**
 * @brief Initialize status LEDs
 * @return 0 on success, negative errno on failure
 */
int leds_init(void);

/**
 * @brief Set the run status LED state
 * @param on true = LED on, false = LED off
 */
void leds_set_run(bool on);

/**
 * @brief Set the connection status LED state
 * @param on true = LED on, false = LED off
 */
void leds_set_connection(bool on);

/**
 * @brief Toggle the run status LED
 */
void leds_toggle_run(void);

#endif /* LEDS_H */
```

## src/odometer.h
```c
/*
 * Odometer module - Pulse counting and trip storage
 *
 * NVM-Direct Architecture:
 * - Only current trip in RAM (~204 bytes)
 * - Completed trips stored directly to NVM
 * - Trips read on-demand from NVM
 * 
 * Capacity with the shared nRF54L10/nRF54L15 storage layout:
 * - Newest 3000 trips retained in a circular archive
 * - Full 5-min bucket detail for retained trips
 * - Stable, monotonically increasing public trip IDs
 */

#ifndef ODOMETER_H
#define ODOMETER_H

#include <stdint.h>
#include <stddef.h>
#include <stdbool.h>

/* Default wheel size: 26" = 2600 hundredths of an inch */
#define DEFAULT_WHEEL_SIZE_X100  2600U

/* Calculate wheel circumference in mm from size_x100 (C = pi * D) */
#define WHEEL_CIRCUMFERENCE_MM(size_x100) \
	((uint32_t)((((uint64_t)(size_x100) * 79796ULL) + 50000ULL) / 100000ULL))

/* Storage configuration - 5-min bins, 4h max sessions */
#define BIN_INTERVAL_MINUTES  5     /* 5-min bins (client requirement) */
#define MAX_TRIPS             3000  /* Newest ~8 years at 1 trip/day */
#define BUCKETS_PER_TRIP      48    /* 48 bins * 5 min = 4 hours max per trip */

/* Trip entry with full bucket detail (~204 bytes each) */
struct trip_entry {
	uint64_t start_timestamp_s;
	uint32_t buckets[BUCKETS_PER_TRIP];  /* pulse counts per bucket */
	uint16_t bucket_count;               /* number of valid buckets */
	uint16_t _reserved;                  /* alignment padding */
};

/**
 * @brief Initialize the odometer (pulse GPIO and bin timer)
 * @return 0 on success, negative errno on failure
 */
int odometer_init(void);

/**
 * @brief Get current pulse count (since last bin)
 */
uint32_t odometer_get_pulse_count(void);

/**
 * @brief Get total trip count stored in NVM
 */
size_t odometer_get_trip_count(void);

/**
 * @brief Get the stable BLE/NVS identifier for a trip index
 * @param index Trip index (0 = oldest, trip_count-1 = newest/current)
 * @return Stable identifier, or 0 if index is invalid
 */
uint32_t odometer_get_trip_id(size_t index);

/**
 * @brief Read a specific trip from NVM
 * @param index Trip index (0 = oldest, trip_count-1 = newest)
 * @param trip_out Pointer to trip_entry struct to fill
 * @return 0 on success, negative errno on failure
 */
int odometer_read_trip(size_t index, struct trip_entry *trip_out);

/**
 * @brief Get pointer to current (active) trip, or NULL if no active trip
 */
const struct trip_entry *odometer_get_current_trip(void);

/**
 * @brief Check if there's an active trip in progress
 */
bool odometer_is_trip_active(void);

/**
 * @brief Load odometer data from NVM
 */
void odometer_load_from_nvm(void);

/**
 * @brief Get wheel size in inches * 100 (e.g., 2630 = 26.30")
 */
uint32_t odometer_get_wheel_size_x100(void);

/**
 * @brief Set wheel size in inches * 100 and persist to NVM
 * @param size_x100 Wheel diameter in hundredths of inches
 */
void odometer_set_wheel_size_x100(uint32_t size_x100);

#endif /* ODOMETER_H */
```

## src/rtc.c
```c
/*
 * RTC module - Software real-time clock implementation
 */

#include "rtc.h"

#include <zephyr/kernel.h>
#include <zephyr/settings/settings.h>


/* State */
static uint64_t base_unix_time;      /* Unix timestamp when time was set */
static int64_t base_uptime_ms;       /* k_uptime_get() when time was set */
static bool time_is_set;

/*
 * Settings handler for loading saved time
 */
#if IS_ENABLED(CONFIG_SETTINGS)
static int rtc_set(const char *name, size_t len,
                   settings_read_cb read_cb, void *cb_arg)
{
    if (strcmp(name, "base") == 0) {
        if (len != sizeof(base_unix_time)) {
            return -EINVAL;
        }
        ssize_t rc = read_cb(cb_arg, &base_unix_time, sizeof(base_unix_time));
        if (rc < 0) {
            return rc;
        }
        /* When loading from NVS, we don't have the original uptime,
         * so we set base_uptime_ms to current uptime. This means
         * the loaded time will be stale (from before sleep/reset),
         * but it's better than nothing until BLE syncs. */
        base_uptime_ms = k_uptime_get();
        time_is_set = (base_unix_time > 0);
        return 0;
    }

    return -ENOENT;
}

SETTINGS_STATIC_HANDLER_DEFINE(rtc, "rtc", NULL, rtc_set, NULL, 0);
#endif

void rtc_init(void)
{
    /* Settings are loaded by main's settings_load() call */
}

void rtc_set_time(uint64_t unix_time)
{
    base_unix_time = unix_time;
    base_uptime_ms = k_uptime_get();
    time_is_set = true;


#if IS_ENABLED(CONFIG_SETTINGS)
    /* Persist to NVS */
    int err = settings_save_one("rtc/base", &base_unix_time, sizeof(base_unix_time));
    if (err) {
    }
#endif
}

uint64_t rtc_get_time(void)
{
    if (!time_is_set) {
        return 0;
    }

    int64_t elapsed_ms = k_uptime_get() - base_uptime_ms;
    uint64_t elapsed_sec = (uint64_t)(elapsed_ms / 1000);

    return base_unix_time + elapsed_sec;
}

uint64_t rtc_get_time_ms(void)
{
    if (!time_is_set) {
        return 0;
    }

    int64_t elapsed_ms = k_uptime_get() - base_uptime_ms;

    return (base_unix_time * 1000ULL) + (uint64_t)elapsed_ms;
}

bool rtc_is_time_set(void)
{
    return time_is_set;
}
```

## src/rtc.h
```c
/*
 * RTC module - Software real-time clock using system uptime
 *
 * Since nRF54L doesn't have a battery-backed RTC, we use a software
 * implementation based on k_uptime_get(). The base time is set via BLE
 * and persisted in NVS.
 *
 * Time accuracy is lost during deep sleep or reset, but is re-synced
 * when the phone reconnects.
 */

#ifndef RTC_H
#define RTC_H

#include <stdint.h>
#include <stdbool.h>

/**
 * @brief Initialize the RTC module
 *
 * Loads the last known time from NVS if available.
 */
void rtc_init(void);

/**
 * @brief Set the current time
 *
 * @param unix_time Unix timestamp (seconds since 1970-01-01 00:00:00 UTC)
 */
void rtc_set_time(uint64_t unix_time);

/**
 * @brief Get the current time
 *
 * @return Unix timestamp, or 0 if time has never been set
 */
uint64_t rtc_get_time(void);

/**
 * @brief Check if time has been set
 *
 * @return true if time has been synchronized via BLE
 */
bool rtc_is_time_set(void);

/**
 * @brief Get time as milliseconds since epoch
 *
 * @return Unix timestamp in milliseconds
 */
uint64_t rtc_get_time_ms(void);

#endif /* RTC_H */
```
